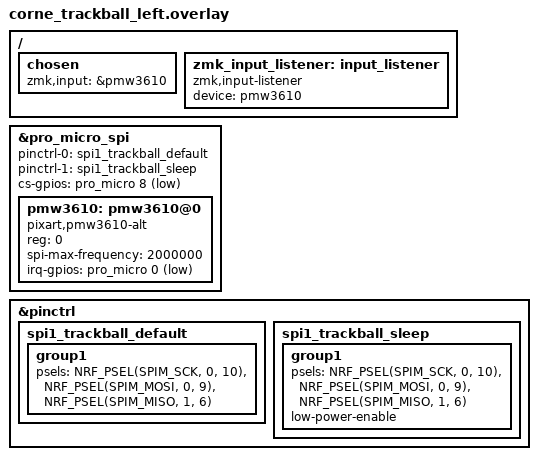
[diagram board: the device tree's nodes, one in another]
/ {
    chosen {
        zmk,input = &pmw3610;
    };
};

&pro_micro_spi {
    status = "okay";
    pinctrl-0 = <&spi1_trackball_default>;
    pinctrl-1 = <&spi1_trackball_sleep>;
    pinctrl-names = "default", "sleep";
    cs-gpios = <&pro_micro 8 GPIO_ACTIVE_LOW>;

    pmw3610: pmw3610@0 {
        compatible = "pixart,pmw3610-alt";
        reg = <0>;
        spi-max-frequency = <2000000>;
        irq-gpios = <&pro_micro 0 GPIO_ACTIVE_LOW>;
    };
};

&pinctrl {
    spi1_trackball_default: spi1_trackball_default {
        group1 {
            psels = <NRF_PSEL(SPIM_SCK, 0, 10)>,
                    <NRF_PSEL(SPIM_MOSI, 0, 9)>,
                    <NRF_PSEL(SPIM_MISO, 1, 6)>;
        };
    };

    spi1_trackball_sleep: spi1_trackball_sleep {
        group1 {
            psels = <NRF_PSEL(SPIM_SCK, 0, 10)>,
                    <NRF_PSEL(SPIM_MOSI, 0, 9)>,
                    <NRF_PSEL(SPIM_MISO, 1, 6)>;
            low-power-enable;
        };
    };
};

/ {
    zmk_input_listener: input_listener {
        compatible = "zmk,input-listener";
        device = <&pmw3610>;
    };
};
